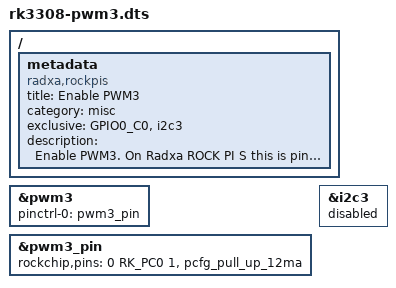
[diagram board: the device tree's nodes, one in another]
/dts-v1/;
/plugin/;

#include <dt-bindings/pinctrl/rockchip.h>

/ {
	metadata {
		title = "Enable PWM3";
		compatible = "radxa,rockpis", "radxa,rock-s0";
		category = "misc";
		exclusive = "GPIO0_C0", "i2c3";
		description = "Enable PWM3.
On Radxa ROCK PI S this is pin 13.
On Radxa ROCK S this is pin 28.";
	};
};

&pwm3 {
	status = "okay";
	pinctrl-names = "default";
	pinctrl-0 = <&pwm3_pin>;
};

&pwm3_pin {
	rockchip,pins =
		<0 RK_PC0 1 &pcfg_pull_up_12ma>;
};

&i2c3 {
	status = "disabled";
};
